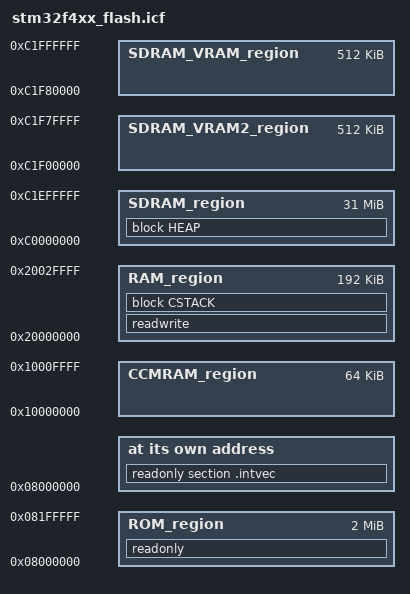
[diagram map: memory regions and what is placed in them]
/*###ICF### Section handled by ICF editor, don't touch! ****/
/*-Editor annotation file-*/
/* IcfEditorFile="$TOOLKIT_DIR$\config\ide\IcfEditor\cortex_v1_0.xml" */
/*-Specials-*/
define symbol __ICFEDIT_intvec_start__ = 0x08000000;
/*-Memory Regions-*/
define symbol __ICFEDIT_region_ROM_start__    = 0x08000000;
define symbol __ICFEDIT_region_ROM_end__      = 0x081FFFFF;
define symbol __ICFEDIT_region_RAM_start__    = 0x20000000;
define symbol __ICFEDIT_region_RAM_end__      = 0x2002FFFF;
/*-Sizes-*/
define symbol __ICFEDIT_size_cstack__ = 0x1000;
define symbol __ICFEDIT_size_heap__   = 0x1F00000;
/**** End of ICF editor section. ###ICF###*/

define symbol __CCMRAM_start__ = 0x10000000;
define symbol __CCMRAM_end__   = 0x1000FFFF;

define symbol __SDRAM_start__  = 0xC0000000;
define symbol __SDRAM_end__    = 0xC1EFFFFF;

define symbol __region_SDRAM_VRAM_start__ =  0xC1F80000;
define symbol __region_SDRAM_VRAM_end__    = 0xC1FFFFFF;

define symbol __region_SDRAM_VRAM2_start__ =  0xC1F00000;
define symbol __region_SDRAM_VRAM2_end__    = 0xC1F7FFFF;

define memory mem with size = 4G;
define region ROM_region      = mem:[from __ICFEDIT_region_ROM_start__   to __ICFEDIT_region_ROM_end__];
define region RAM_region      = mem:[from __ICFEDIT_region_RAM_start__   to __ICFEDIT_region_RAM_end__];
define region CCMRAM_region   = mem:[from __CCMRAM_start__   to __CCMRAM_end__];

define region SDRAM_region       = mem:[from __SDRAM_start__   to __SDRAM_end__];
define region SDRAM_VRAM_region  = mem:[from __region_SDRAM_VRAM_start__  to __region_SDRAM_VRAM_end__];
define region SDRAM_VRAM2_region = mem:[from __region_SDRAM_VRAM2_start__  to __region_SDRAM_VRAM2_end__];

define block CSTACK    with alignment = 8, size = __ICFEDIT_size_cstack__   { };
define block HEAP      with alignment = 8, size = __ICFEDIT_size_heap__     { };

initialize by copy { readwrite };
do not initialize  { section .noinit };

place at address mem:__ICFEDIT_intvec_start__ { readonly section .intvec };

place in ROM_region   { readonly };
place in RAM_region   { readwrite,
                        block CSTACK };

place in SDRAM_region
                      { block HEAP };

define exported symbol SDRAM_BASE_ADDR = __SDRAM_start__;
define exported symbol SDRAM_VRAM_BASE_ADDR = __region_SDRAM_VRAM_start__;
define exported symbol SDRAM_VRAM2_BASE_ADDR = __region_SDRAM_VRAM2_start__;
